VERSION ""

NS_ :

BS_:

BU_: XXX

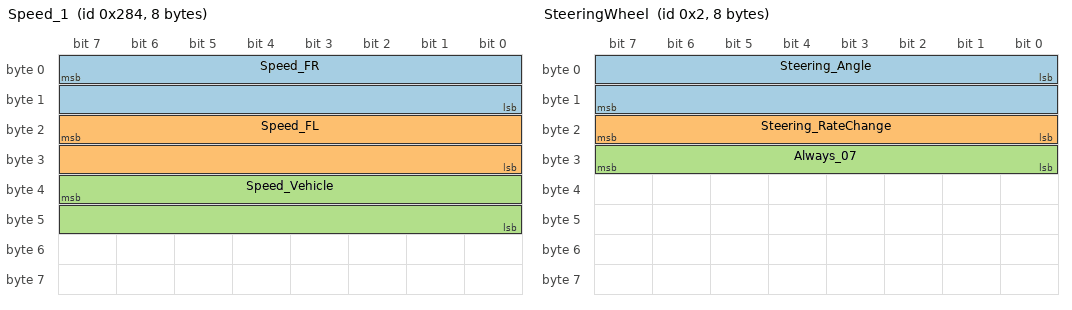
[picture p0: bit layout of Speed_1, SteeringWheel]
BO_ 644 Speed_1: 8 XXX
 SG_ Speed_FR : 7|16@0+ (0.0118,0) [0|65535] "" XXX
 SG_ Speed_FL : 23|16@0+ (0.0118,0) [0|65535] "" XXX
 SG_ Speed_Vehicle : 39|16@0+ (0.0245,0) [0|65535] "" XXX

BO_ 645 Speed_2: 8 XXX
 SG_ Speed_RR : 7|16@0+ (0.0118,0) [0|65535] "" XXX
 SG_ Speed_RL : 23|16@0+ (0.0118,0) [0|65535] "" XXX

BO_ 768 STEER_TORQUE: 8 XXX
 SG_ STEERING_TOURQUE : 0|7@1+ (1,0) [0|127] "" XXX

BO_ 459 Maybe_RegenBraking: 8 XXX

BO_ 372 Maybe_Gear_Selector: 8 XXX
 SG_ Counter : 32|4@1+ (1,0) [0|15] "" XXX

BO_ 374 Maybe_Motor_RPM_or_Speed: 8 XXX
 SG_ Counter : 48|4@1+ (1,0) [0|15] "" XXX

BO_ 460 Maybe_Brake_Related: 8 XXX

BO_ 2 SteeringWheel: 8 XXX
 SG_ Steering_Angle : 0|16@1- (1,0) [0|65535] "" XXX
 SG_ Steering_RateChange : 23|8@0+ (1,0) [0|255] "" XXX
 SG_ Always_07 : 31|8@0+ (1,0) [0|255] "" XXX

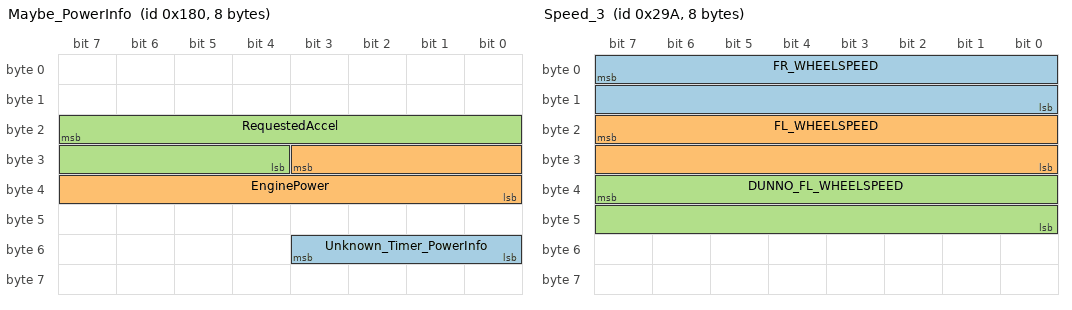
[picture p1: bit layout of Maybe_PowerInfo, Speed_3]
BO_ 384 Maybe_PowerInfo: 8 XXX
 SG_ Unknown_Timer_PowerInfo : 48|4@1+ (1,0) [0|15] "" XXX
 SG_ EnginePower : 27|12@0- (1,0) [0|1] "" XXX
 SG_ RequestedAccel : 23|12@0- (1,0) [0|4294967295] "" XXX

BO_ 1376 NEW_MSG_1: 8 XXX

BO_ 666 Speed_3: 8 XXX
 SG_ FR_WHEELSPEED : 7|16@0+ (1,0) [0|65535] "" XXX
 SG_ FL_WHEELSPEED : 23|16@0+ (1,0) [0|65535] "" XXX
 SG_ DUNNO_FL_WHEELSPEED : 39|16@0+ (1,0) [0|65535] "" XXX

BO_ 398 NEW_MSG_2: 8 XXX

BO_ 389 NEW_MSG_3: 8 XXX
 SG_ NEW_SIGNAL_1 : 15|8@0+ (1,0) [0|255] "" XXX
 SG_ NEW_SIGNAL_2 : 22|6@0+ (1,0) [0|3] "" XXX
 SG_ NEW_SIGNAL_3 : 23|16@0+ (1,0) [0|255] "" XXX
 SG_ NEW_SIGNAL_4 : 47|8@0+ (1,0) [0|255] "" XXX
 SG_ NEW_SIGNAL_5 : 55|8@0+ (1,0) [0|255] "" XXX
 SG_ NEW_SIGNAL_6 : 63|8@0+ (1,0) [0|127] "" XXX

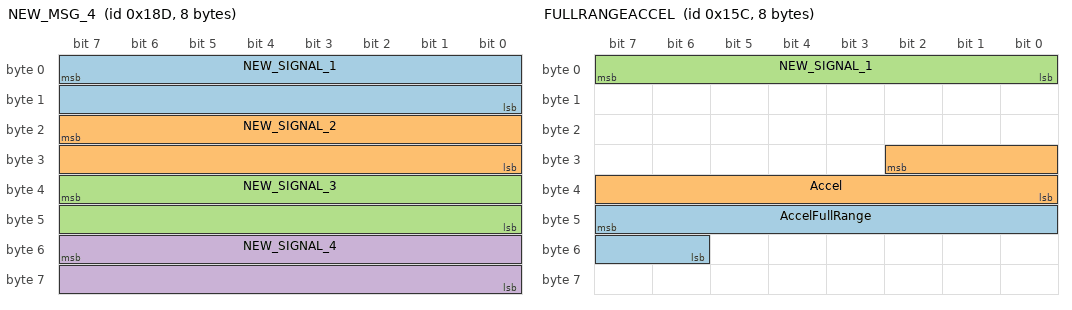
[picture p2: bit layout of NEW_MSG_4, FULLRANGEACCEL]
BO_ 397 NEW_MSG_4: 8 XXX
 SG_ NEW_SIGNAL_1 : 7|16@0+ (1,0) [0|3] "" XXX
 SG_ NEW_SIGNAL_2 : 23|16@0+ (1,0) [0|32767] "" XXX
 SG_ NEW_SIGNAL_3 : 39|16@0+ (1,0) [0|65535] "" XXX
 SG_ NEW_SIGNAL_4 : 55|16@0+ (1,0) [0|31] "" XXX

BO_ 658 NEW_MSG_5: 8 XXX
 SG_ NEW_SIGNAL_1 : 7|16@0+ (1,0) [0|255] "" XXX

BO_ 855 NEW_MSG_6: 8 XXX
 SG_ NEW_SIGNAL_1 : 7|8@0+ (1,0) [0|255] "" XXX

BO_ 773 NEW_MSG_7: 8 XXX
 SG_ NEW_SIGNAL_1 : 39|8@0+ (1,0) [0|255] "" XXX
 SG_ NEW_SIGNAL_2 : 47|8@0+ (1,0) [0|255] "" XXX

BO_ 851 SPEED_RELATED: 8 XXX
 SG_ SPEED_RELATED : 7|16@0+ (1,0) [0|65535] "" XXX

BO_ 386 Accelerator: 8 XXX
 SG_ Accelerator : 38|7@0+ (1,0) [0|127] "" XXX

BO_ 347 ACCELSOMETHING: 8 XXX
 SG_ PowerMaybe : 9|10@0+ (1,0) [0|1023] "" XXX
 SG_ ACCELERATOR2 : 6|11@0+ (1,-800) [0|65535] "" XXX

BO_ 346 ANOTHER_ACCEL: 8 XXX
 SG_ ANOTHERACCEL : 23|10@0+ (1,0) [0|1023] "" XXX
 SG_ Reverse_ACCEL : 25|10@0+ (1,0) [0|1023] "" XXX

BO_ 348 FULLRANGEACCEL: 8 XXX
 SG_ AccelFullRange : 47|10@0+ (1,0) [0|1023] "" XXX
 SG_ Accel : 26|11@0+ (1,0) [0|2047] "" XXX
 SG_ NEW_SIGNAL_1 : 7|8@0+ (1,0) [0|255] "" XXX

BO_ 566 ANOTHERFULLRANGEACCEL: 8 XXX
 SG_ ANOTHERFULLRANGEACCEL : 43|8@0+ (1,0) [0|1023] "" XXX
 SG_ RPMORTORQUE : 31|8@0+ (1,0) [0|255] "" XXX

BO_ 523 Yetyetanotheraccel: 8 XXX
 SG_ ANOTHERREVERSEACCEL : 37|10@0+ (1,0) [0|1023] "" XXX
 SG_ yetyetanotheraccel : 31|10@0+ (1,0) [0|255] "" XXX

BO_ 779 ANOTHERRRFULLRANGEACCEL: 8 XXX
 SG_ ANOTHERRRFULLRANGEACCEL : 47|8@0+ (1,0) [0|255] "" XXX

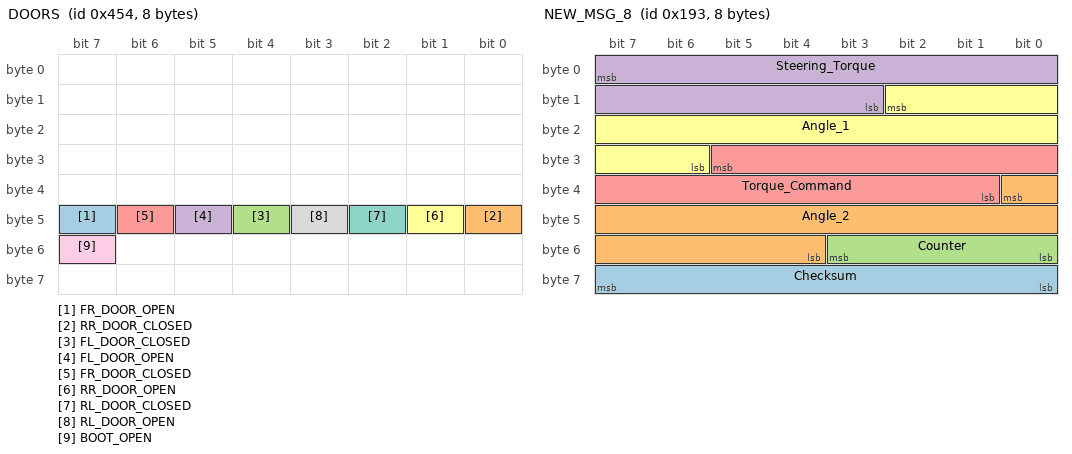
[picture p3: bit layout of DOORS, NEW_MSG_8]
BO_ 1108 DOORS: 8 XXX
 SG_ FR_DOOR_OPEN : 47|1@0+ (1,0) [0|3] "" XXX
 SG_ RR_DOOR_CLOSED : 40|1@0+ (1,0) [0|1] "" XXX
 SG_ FL_DOOR_CLOSED : 44|1@0+ (1,0) [0|1] "" XXX
 SG_ FL_DOOR_OPEN : 45|1@0+ (1,0) [0|1] "" XXX
 SG_ FR_DOOR_CLOSED : 46|1@0+ (1,0) [0|3] "" XXX
 SG_ RR_DOOR_OPEN : 41|1@0+ (1,0) [0|1] "" XXX
 SG_ RL_DOOR_CLOSED : 42|1@0+ (1,0) [0|1] "" XXX
 SG_ RL_DOOR_OPEN : 43|1@0+ (1,0) [0|1] "" XXX
 SG_ BOOT_OPEN : 55|1@0+ (1,0) [0|1] "" XXX

BO_ 403 NEW_MSG_8: 8 XXX
 SG_ Checksum : 63|8@0+ (1,0) [0|255] "" XXX
 SG_ Angle_2 : 32|13@0+ (1,-4000) [0|63] "" XXX
 SG_ Counter : 48|4@1+ (1,0) [0|15] "" XXX
 SG_ Steering_Torque : 7|13@0+ (-1,4000) [0|65535] "" XXX
 SG_ Torque_Command : 29|13@0+ (1,-4000) [0|255] "" XXX
 SG_ Angle_1 : 10|13@0+ (0.12,-480) [0|65535] "" XXX

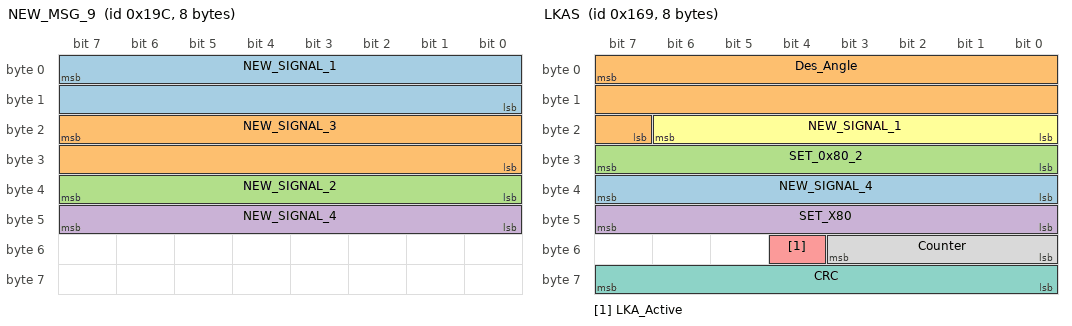
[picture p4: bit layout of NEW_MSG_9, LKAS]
BO_ 412 NEW_MSG_9: 8 XXX
 SG_ NEW_SIGNAL_1 : 7|16@0+ (1,0) [0|65535] "" XXX
 SG_ NEW_SIGNAL_3 : 23|16@0+ (1,0) [0|65535] "" XXX
 SG_ NEW_SIGNAL_2 : 39|8@0+ (1,0) [0|3] "" XXX
 SG_ NEW_SIGNAL_4 : 47|8@0+ (1,0) [0|255] "" XXX

BO_ 361 LKAS: 8 XXX
 SG_ NEW_SIGNAL_4 : 39|8@0+ (1,0) [0|255] "" XXX
 SG_ Des_Angle : 7|17@0+ (1,0) [0|255] "" XXX
 SG_ SET_0x80_2 : 31|8@0+ (1,0) [0|255] "" XXX
 SG_ SET_X80 : 47|8@0+ (1,0) [0|255] "" XXX
 SG_ LKA_Active : 52|1@0+ (1,0) [0|15] "" XXX
 SG_ NEW_SIGNAL_1 : 16|7@1+ (1,0) [0|63] "" XXX
 SG_ CRC : 63|8@0+ (1,0) [0|255] "" XXX
 SG_ Counter : 48|4@1+ (1,0) [0|15] "" XXX

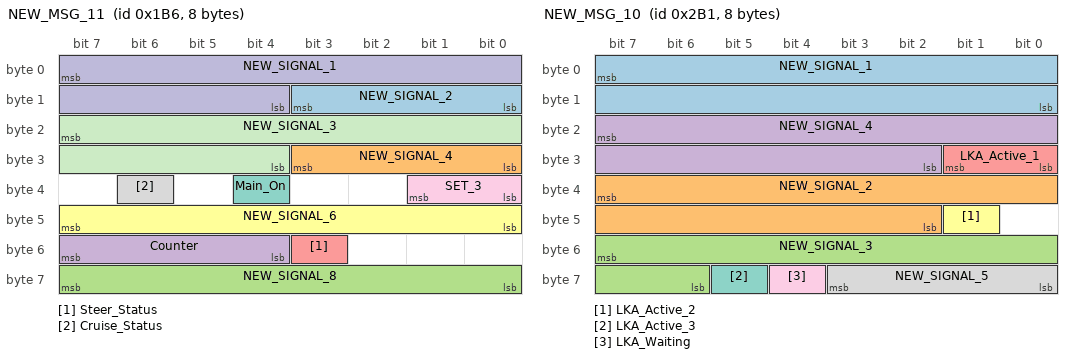
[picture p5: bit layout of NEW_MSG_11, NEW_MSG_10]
BO_ 438 NEW_MSG_11: 8 XXX
 SG_ NEW_SIGNAL_2 : 11|4@0+ (1,0) [0|255] "" XXX
 SG_ NEW_SIGNAL_4 : 27|4@0+ (1,0) [0|255] "" XXX
 SG_ NEW_SIGNAL_8 : 63|8@0+ (1,0) [0|7] "" XXX
 SG_ Counter : 55|4@0+ (1,0) [0|255] "" XXX
 SG_ Steer_Status : 51|1@1+ (1,0) [0|3] "" XXX
 SG_ NEW_SIGNAL_6 : 47|8@0+ (1,0) [0|255] "" XXX
 SG_ Main_On : 36|1@0+ (1,0) [0|255] "" XXX
 SG_ Cruise_Status : 38|1@0+ (1,0) [0|3] "" XXX
 SG_ SET_3 : 32|2@1+ (1,0) [0|15] "" XXX
 SG_ NEW_SIGNAL_1 : 7|12@0- (1,0) [0|255] "" XXX
 SG_ NEW_SIGNAL_3 : 23|12@0- (-1,0) [0|255] "" XXX

BO_ 783 NEW_MSG_12: 8 XXX
 SG_ NEW_SIGNAL_1 : 23|8@0+ (1,0) [0|4095] "" XXX
 SG_ NEW_SIGNAL_2 : 8|4@1+ (1,0) [0|15] "" XXX

BO_ 689 NEW_MSG_10: 8 XXX
 SG_ NEW_SIGNAL_1 : 7|16@0+ (1,0) [0|8191] "" XXX
 SG_ NEW_SIGNAL_2 : 39|14@0+ (1,0) [0|16777215] "" XXX
 SG_ NEW_SIGNAL_3 : 55|10@0+ (1,0) [0|65535] "" XXX
 SG_ NEW_SIGNAL_4 : 23|14@0+ (1,0) [0|65535] "" XXX
 SG_ LKA_Active_1 : 24|2@1+ (1,0) [0|3] "" XXX
 SG_ LKA_Active_2 : 41|1@1+ (1,0) [0|3] "" XXX
 SG_ LKA_Active_3 : 61|1@0+ (1,0) [0|3] "" XXX
 SG_ NEW_SIGNAL_5 : 56|4@1+ (1,0) [0|31] "" XXX
 SG_ LKA_Waiting : 60|1@0+ (1,0) [0|3] "" XXX

CM_ SG_ 689 LKA_Waiting "ACC Engaged, LKA not sending";
